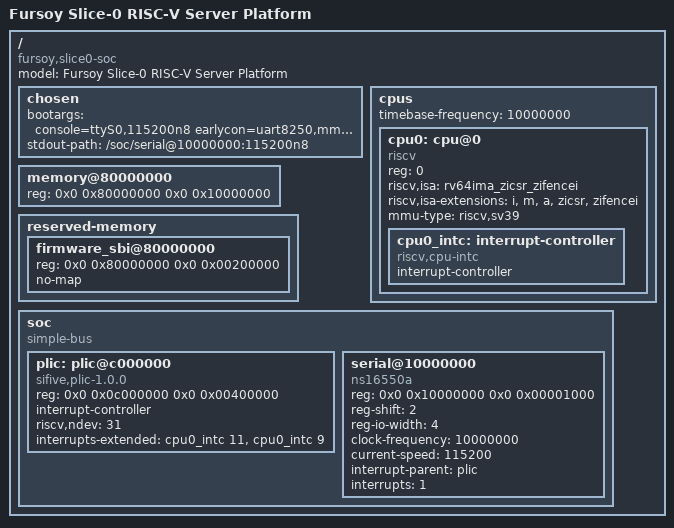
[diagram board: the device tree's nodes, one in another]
/dts-v1/;

/ {
    #address-cells = <2>;
    #size-cells = <2>;
    compatible = "fursoy,slice0-soc", "fursoy,fursoy-s0";
    model = "Fursoy Slice-0 RISC-V Server Platform";

    chosen {
        bootargs = "console=ttyS0,115200n8 earlycon=uart8250,mmio32,0x10000000 root=/dev/ram0 rw";
        stdout-path = "/soc/serial@10000000:115200n8";
    };

    cpus {
        #address-cells = <1>;
        #size-cells = <0>;
        timebase-frequency = <10000000>; /* 10 MHz CLINT timebase */

        cpu0: cpu@0 {
            device_type = "cpu";
            reg = <0>;
            status = "okay";
            compatible = "riscv";
            riscv,isa = "rv64ima_zicsr_zifencei";
            riscv,isa-extensions = "i", "m", "a", "zicsr", "zifencei";
            mmu-type = "riscv,sv39";

            cpu0_intc: interrupt-controller {
                #interrupt-cells = <1>;
                compatible = "riscv,cpu-intc";
                interrupt-controller;
            };
        };
    };

    memory@80000000 {
        device_type = "memory";
        reg = <0x0 0x80000000 0x0 0x10000000>; /* Full 256 MiB physical DRAM */
    };

    reserved-memory {
        #address-cells = <2>;
        #size-cells = <2>;
        ranges;

        firmware_sbi@80000000 {
            reg = <0x0 0x80000000 0x0 0x00200000>; /* 2 MiB M-mode reservation */
            no-map;
        };
    };

    soc {
        #address-cells = <2>;
        #size-cells = <2>;
        compatible = "simple-bus";
        ranges;

        plic: plic@c000000 {
            compatible = "sifive,plic-1.0.0", "riscv,plic0";
            reg = <0x0 0x0c000000 0x0 0x00400000>;
            interrupt-controller;
            #interrupt-cells = <1>;
            riscv,ndev = <31>;
            interrupts-extended = <&cpu0_intc 11 &cpu0_intc 9>; /* Context 0 M, Context 1 S */
        };

        serial@10000000 {
            compatible = "ns16550a";
            reg = <0x0 0x10000000 0x0 0x00001000>;
            reg-shift = <2>;
            reg-io-width = <4>;
            clock-frequency = <10000000>;
            current-speed = <115200>;
            interrupt-parent = <&plic>;
            interrupts = <1>; /* PLIC external interrupt source 1 */
        };
    };
};
